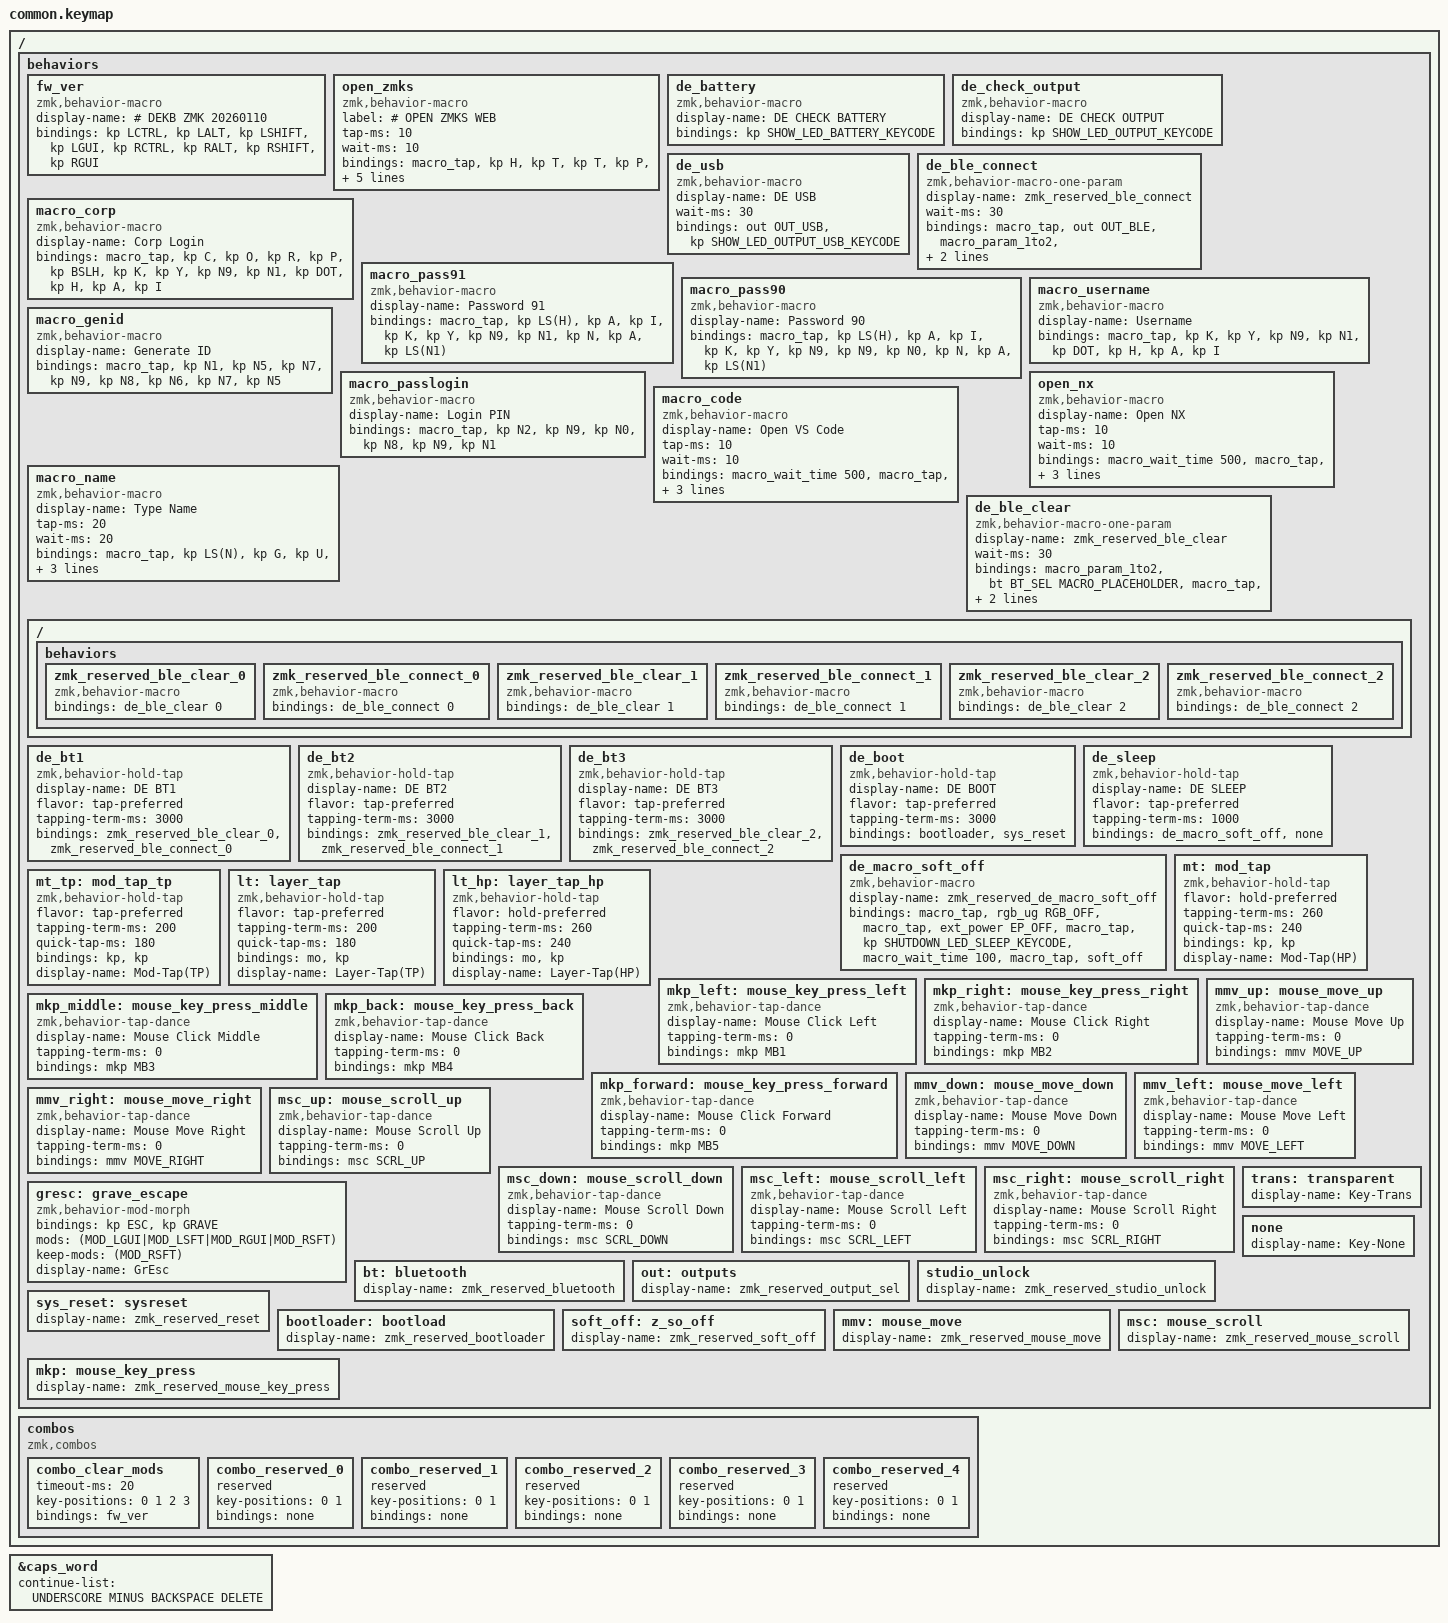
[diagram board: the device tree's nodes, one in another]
/*
 * Copyright (c) 2026 DEKB
 *
 * SPDX-License-Identifier: MIT
 */
 
#define ZMK_BEHAVIORS_OMIT_CAPS_WORD        // &caps_word
#define ZMK_BEHAVIORS_OMIT_KT               // &kt, Key Toggle
#define ZMK_BEHAVIORS_OMIT_KEY_REPEAT       // &key_repeat, Key Repeat
#define ZMK_BEHAVIORS_OMIT_SK               // &sk, Sticky Key
#define ZMK_BEHAVIORS_OMIT_STICKY_LAYER     // &sl, Sticky Layer

#include <behaviors.dtsi>
#include <dt-bindings/zmk/keys.h>
#include <dt-bindings/zmk/pointing.h>
#include <dt-bindings/zmk/bt.h>
#include <dt-bindings/zmk/outputs.h>
#include <dt-bindings/zmk/ext_power.h>
#include <dt-bindings/zmk/rgb.h>

#define ZMK_POINTING_DEFAULT_MOVE_VAL 1000  // default: 600
#define ZMK_POINTING_DEFAULT_SCRL_VAL 80    // default: 10

#define SHUTDOWN_LED_SLEEP_KEYCODE 0xDE01
#define SHOW_LED_BATTERY_KEYCODE 0xDE02
#define SHOW_LED_OUTPUT_KEYCODE 0xDE03
#define SHOW_LED_OUTPUT_USB_KEYCODE 0xDE04
#define SHOW_LED_BLE_PROFILE_STATUS_KEYCODE 0xDE05
#define DE_KEYCODE_BUZZER_TOGGLE 0xDE06

#define DE_BLD de_boot 0 0
#define DE_OUT de_check_output
#define DE_USB de_usb
#define DE_BT1 de_bt1 0 0
#define DE_BT2 de_bt2 0 1
#define DE_BT3 de_bt3 0 2
#define DE_BAT de_battery
#define DE_SLP de_sleep 0 0

#define DE_OZW open_zmks

#define UGTOG rgb_ug RGB_TOG
#define UGBRD rgb_ug RGB_BRD
#define UGBRI rgb_ug RGB_BRI
#define UGHUD rgb_ug RGB_HUD
#define UGHUI rgb_ug RGB_HUI
#define UGSAI rgb_ug RGB_SAI
#define UGSAD rgb_ug RGB_SAD
#define UGSPI rgb_ug RGB_SPI
#define UGSPD rgb_ug RGB_SPD
#define UGEFR rgb_ug RGB_EFR
#define UGEFF rgb_ug RGB_EFF

&caps_word {
    continue-list = <
        UNDERSCORE 
        MINUS 
        BACKSPACE 
        DELETE
    >;
};

/ {
    behaviors {

        fw_ver: fw_ver {
            compatible = "zmk,behavior-macro";
            #binding-cells = <0>;
            display-name = "# DEKB ZMK 20260110";
            bindings = <&kp LCTRL &kp LALT &kp LSHIFT &kp LGUI &kp RCTRL &kp RALT &kp RSHIFT &kp RGUI>;
        };

        open_zmks: open_zmks {
            compatible = "zmk,behavior-macro";
            label = "# OPEN ZMKS WEB";
            #binding-cells = <0>;
            tap-ms = <10>;  
            wait-ms = <10>;  
            bindings
                = <&macro_tap &kp H &kp T &kp T &kp P &kp S &kp COLON &kp FSLH &kp FSLH> // https://
                , <&macro_tap &kp Z &kp M &kp K &kp S &kp DOT>                            // zmks.
                , <&macro_tap &kp P &kp H &kp D &kp E &kp S &kp I &kp G &kp N &kp DOT>    // phdesign.
                , <&macro_tap &kp C &kp C &kp ENTER>                                      // cc + Enter để chạy luôn
                ;
        };

        de_battery: de_battery {
            compatible = "zmk,behavior-macro";
            display-name = "DE CHECK BATTERY";
            #binding-cells = <0>;
            bindings = <&kp SHOW_LED_BATTERY_KEYCODE>;
        };

        de_check_output: de_check_output {
            compatible = "zmk,behavior-macro";
            display-name = "DE CHECK OUTPUT";
            #binding-cells = <0>;
            bindings = <&kp SHOW_LED_OUTPUT_KEYCODE>;
        };

        de_usb: de_usb {
            compatible = "zmk,behavior-macro";
            display-name = "DE USB";
            #binding-cells = <0>;
            wait-ms = <30>;
            bindings = <&out OUT_USB>, <&kp SHOW_LED_OUTPUT_USB_KEYCODE>;
        };

        de_ble_connect: de_ble_connect {
            compatible = "zmk,behavior-macro-one-param";
            #binding-cells = <1>;
            display-name = "zmk_reserved_ble_connect";
            wait-ms = <30>;
            bindings = 
                <&macro_tap &out OUT_BLE>,
                <&macro_param_1to2>, <&bt BT_SEL MACRO_PLACEHOLDER>,
                <&macro_tap &kp SHOW_LED_BLE_PROFILE_STATUS_KEYCODE>;
        };

        /* Shared personal macros used by Proto and Rev1 keymaps. */
        macro_corp: macro_corp {
            compatible = "zmk,behavior-macro";
            #binding-cells = <0>;
            display-name = "Corp Login";
            bindings = <&macro_tap &kp C &kp O &kp R &kp P &kp BSLH &kp K &kp Y &kp N9 &kp N1 &kp DOT &kp H &kp A &kp I>;
        };

        macro_pass91: macro_pass91 {
            compatible = "zmk,behavior-macro";
            #binding-cells = <0>;
            display-name = "Password 91";
            bindings = <&macro_tap &kp LS(H) &kp A &kp I &kp K &kp Y &kp N9 &kp N1 &kp N &kp A &kp LS(N1)>;
        };

        macro_pass90: macro_pass90 {
            compatible = "zmk,behavior-macro";
            #binding-cells = <0>;
            display-name = "Password 90";
            bindings = <&macro_tap &kp LS(H) &kp A &kp I &kp K &kp Y &kp N9 &kp N9 &kp N0 &kp N &kp A &kp LS(N1)>;
        };

        macro_username: macro_username {
            compatible = "zmk,behavior-macro";
            #binding-cells = <0>;
            display-name = "Username";
            bindings = <&macro_tap &kp K &kp Y &kp N9 &kp N1 &kp DOT &kp H &kp A &kp I>;
        };

        macro_genid: macro_genid {
            compatible = "zmk,behavior-macro";
            #binding-cells = <0>;
            display-name = "Generate ID";
            bindings = <&macro_tap &kp N1 &kp N5 &kp N7 &kp N9 &kp N8 &kp N6 &kp N7 &kp N5>;
        };

        macro_passlogin: macro_passlogin {
            compatible = "zmk,behavior-macro";
            #binding-cells = <0>;
            display-name = "Login PIN";
            bindings = <&macro_tap &kp N2 &kp N9 &kp N0 &kp N8 &kp N9 &kp N1>;
        };

        open_nx: open_nx {
            compatible = "zmk,behavior-macro";
            #binding-cells = <0>;
            display-name = "Open NX";
            tap-ms = <10>;
            wait-ms = <10>;
            bindings = <&macro_wait_time 500>, <&macro_tap &kp LGUI>,
                       <&macro_wait_time 10>, <&macro_tap &kp N>,
                       <&macro_wait_time 500>, <&macro_tap &kp X>,
                       <&macro_tap &kp RET>;
        };

        macro_code: macro_code {
            compatible = "zmk,behavior-macro";
            #binding-cells = <0>;
            display-name = "Open VS Code";
            tap-ms = <10>;
            wait-ms = <10>;
            bindings = <&macro_wait_time 500>, <&macro_tap &kp LGUI>,
                       <&macro_wait_time 10>, <&macro_tap &kp C &kp O &kp D>,
                       <&macro_wait_time 500>, <&macro_tap &kp E>,
                       <&macro_tap &kp RET>;
        };

        macro_name: macro_name {
            compatible = "zmk,behavior-macro";
            #binding-cells = <0>;
            display-name = "Type Name";
            tap-ms = <20>;
            wait-ms = <20>;
            bindings = <&macro_tap &kp LS(N) &kp G &kp U &kp Y &kp E &kp E &kp N &kp X
                                   &kp SPACE &kp LS(H) &kp A &kp I &kp R
                                   &kp SPACE &kp LS(K) &kp Y &kp R>;
        };

        de_ble_clear: de_ble_clear {
            compatible = "zmk,behavior-macro-one-param";
            #binding-cells = <1>;
            display-name = "zmk_reserved_ble_clear";
            wait-ms = <30>;
            bindings = 
                <&macro_param_1to2>, <&bt BT_SEL MACRO_PLACEHOLDER>,
                <&macro_tap &bt BT_CLR>,
                <&macro_tap &kp SHOW_LED_BLE_PROFILE_STATUS_KEYCODE>;
        };
        
        ZMK_MACRO(zmk_reserved_ble_clear_0, bindings = <&de_ble_clear 0> ;)
        ZMK_MACRO(zmk_reserved_ble_connect_0, bindings = <&de_ble_connect 0>;)
        ZMK_MACRO(zmk_reserved_ble_clear_1, bindings = <&de_ble_clear 1> ;)
        ZMK_MACRO(zmk_reserved_ble_connect_1, bindings = <&de_ble_connect 1> ;)
        ZMK_MACRO(zmk_reserved_ble_clear_2, bindings = <&de_ble_clear 2> ;)
        ZMK_MACRO(zmk_reserved_ble_connect_2, bindings = <&de_ble_connect 2> ;)

        de_bt1: de_bt1 {
            compatible = "zmk,behavior-hold-tap";
            display-name = "DE BT1";
            #binding-cells = <2>;
            flavor = "tap-preferred";
            tapping-term-ms = <3000>;
            bindings = <&zmk_reserved_ble_clear_0>, <&zmk_reserved_ble_connect_0>;
        };
        de_bt2: de_bt2 {
            compatible = "zmk,behavior-hold-tap";
            display-name = "DE BT2";
            #binding-cells = <2>;
            flavor = "tap-preferred";
            tapping-term-ms = <3000>;
            bindings = <&zmk_reserved_ble_clear_1>, <&zmk_reserved_ble_connect_1>;
        };
        de_bt3: de_bt3 {
            compatible = "zmk,behavior-hold-tap";
            display-name = "DE BT3";
            #binding-cells = <2>;
            flavor = "tap-preferred";
            tapping-term-ms = <3000>;
            bindings = <&zmk_reserved_ble_clear_2>, <&zmk_reserved_ble_connect_2>;
        };

        de_boot: de_boot {
            compatible = "zmk,behavior-hold-tap";
            display-name = "DE BOOT";
            #binding-cells = <2>;
            flavor = "tap-preferred";
            tapping-term-ms = <3000>;  
            bindings = <&bootloader>, <&sys_reset>;
        };

        de_sleep: de_sleep {
            compatible = "zmk,behavior-hold-tap";
            display-name = "DE SLEEP";
            #binding-cells = <2>;
            flavor = "tap-preferred";
            tapping-term-ms = <1000>; 
            bindings = <&de_macro_soft_off>, <&none>;
        };

        de_macro_soft_off: de_macro_soft_off {
            compatible = "zmk,behavior-macro";
            #binding-cells = <0>;
            display-name = "zmk_reserved_de_macro_soft_off";
            bindings = <
                &macro_tap &rgb_ug RGB_OFF
                &macro_tap &ext_power EP_OFF
                &macro_tap &kp SHUTDOWN_LED_SLEEP_KEYCODE
                &macro_wait_time 100
                &macro_tap &soft_off
            >;
        };

        // mo: momentary_layer { display-name = "Layer Momentary"; };
        // to: to_layer { display-name = "Layer To"; };
        // tog: toggle_layer { display-name = "Layer Toggle"; };

        mt: mod_tap {
            compatible = "zmk,behavior-hold-tap";
            #binding-cells = <2>;
            flavor = "hold-preferred";
            tapping-term-ms = <260>;
            quick-tap-ms = <240>;
            bindings = <&kp>, <&kp>;
            display-name = "Mod-Tap(HP)";
        };

        mt_tp: mod_tap_tp {
            compatible = "zmk,behavior-hold-tap";
            #binding-cells = <2>;
            flavor = "tap-preferred";
            tapping-term-ms = <200>;
            quick-tap-ms = <180>;
            bindings = <&kp>, <&kp>;
            display-name = "Mod-Tap(TP)";
        };

        lt: layer_tap {
            compatible = "zmk,behavior-hold-tap";
            #binding-cells = <2>;
            flavor = "tap-preferred";
            tapping-term-ms = <200>;
            quick-tap-ms = <180>;
            bindings = <&mo>, <&kp>;
            display-name = "Layer-Tap(TP)";
        };

        lt_hp: layer_tap_hp {
            compatible = "zmk,behavior-hold-tap";
            #binding-cells = <2>;
            flavor = "hold-preferred";
            tapping-term-ms = <260>;
            quick-tap-ms = <240>;
            bindings = <&mo>, <&kp>;
            display-name = "Layer-Tap(HP)";
        };
        
        // Mouse 
        mkp_left: mouse_key_press_left {
            compatible = "zmk,behavior-tap-dance";
            display-name = "Mouse Click Left";
            #binding-cells = <0>;
            tapping-term-ms = <0>;
            bindings = <&mkp MB1>;
        };
        mkp_right: mouse_key_press_right {
            compatible = "zmk,behavior-tap-dance";
            display-name = "Mouse Click Right";
            #binding-cells = <0>;
            tapping-term-ms = <0>;
            bindings = <&mkp MB2>;
        };
        mkp_middle: mouse_key_press_middle {
            compatible = "zmk,behavior-tap-dance";
            display-name = "Mouse Click Middle";
            #binding-cells = <0>;
            tapping-term-ms = <0>;
            bindings = <&mkp MB3>;
        };
        mkp_back: mouse_key_press_back {
            compatible = "zmk,behavior-tap-dance";
            display-name = "Mouse Click Back";
            #binding-cells = <0>;
            tapping-term-ms = <0>;
            bindings = <&mkp MB4>;
        };
        mkp_forward: mouse_key_press_forward {
            compatible = "zmk,behavior-tap-dance";
            display-name = "Mouse Click Forward";
            #binding-cells = <0>;
            tapping-term-ms = <0>;
            bindings = <&mkp MB5>;
        };
        mmv_up: mouse_move_up {
            compatible = "zmk,behavior-tap-dance";
            display-name = "Mouse Move Up";
            #binding-cells = <0>;
            tapping-term-ms = <0>;
            bindings = <&mmv MOVE_UP>;
        };
        mmv_down: mouse_move_down {
            compatible = "zmk,behavior-tap-dance";
            display-name = "Mouse Move Down";
            #binding-cells = <0>;
            tapping-term-ms = <0>;
            bindings = <&mmv MOVE_DOWN>;
        };
        mmv_left: mouse_move_left {
            compatible = "zmk,behavior-tap-dance";
            display-name = "Mouse Move Left";
            #binding-cells = <0>;
            tapping-term-ms = <0>;
            bindings = <&mmv MOVE_LEFT>;
        };
        mmv_right: mouse_move_right {
            compatible = "zmk,behavior-tap-dance";
            display-name = "Mouse Move Right";
            #binding-cells = <0>;
            tapping-term-ms = <0>;
            bindings = <&mmv MOVE_RIGHT>;
        };
        msc_up: mouse_scroll_up {
            compatible = "zmk,behavior-tap-dance";
            display-name = "Mouse Scroll Up";
            #binding-cells = <0>;
            tapping-term-ms = <0>;
            bindings = <&msc SCRL_UP>;
        };
        msc_down: mouse_scroll_down {
            compatible = "zmk,behavior-tap-dance";
            display-name = "Mouse Scroll Down";
            #binding-cells = <0>;
            tapping-term-ms = <0>;
            bindings = <&msc SCRL_DOWN>;
        };
        msc_left: mouse_scroll_left {
            compatible = "zmk,behavior-tap-dance";
            display-name = "Mouse Scroll Left";
            #binding-cells = <0>;
            tapping-term-ms = <0>;
            bindings = <&msc SCRL_LEFT>;
        };
        msc_right: mouse_scroll_right {
            compatible = "zmk,behavior-tap-dance";
            display-name = "Mouse Scroll Right";
            #binding-cells = <0>;
            tapping-term-ms = <0>;
            bindings = <&msc SCRL_RIGHT>;
        };

        gresc: grave_escape {
            compatible = "zmk,behavior-mod-morph";
            #binding-cells = <0>;
            bindings = <&kp ESC>, <&kp GRAVE>;
            mods = <(MOD_LGUI|MOD_LSFT|MOD_RGUI|MOD_RSFT)>;
            keep-mods = <(MOD_RSFT)>;
            display-name = "GrEsc";
        };

        trans: transparent { display-name ="Key-Trans"; };
        none: none { display-name = "Key-None"; };
        bt: bluetooth { display-name = "zmk_reserved_bluetooth"; };
        out: outputs { display-name = "zmk_reserved_output_sel"; };
        studio_unlock: studio_unlock { display-name = "zmk_reserved_studio_unlock"; };
        sys_reset: sysreset { display-name = "zmk_reserved_reset"; };
        bootloader: bootload { display-name = "zmk_reserved_bootloader"; };
        soft_off: z_so_off { display-name = "zmk_reserved_soft_off"; };
        mmv: mouse_move { display-name = "zmk_reserved_mouse_move"; };
        msc: mouse_scroll { display-name = "zmk_reserved_mouse_scroll"; };
        mkp: mouse_key_press { display-name = "zmk_reserved_mouse_key_press"; };
    };

    combos {
        compatible = "zmk,combos";
        combo_clear_mods {
            timeout-ms = <20>;
            key-positions = <0 1 2 3>;
            bindings = <&fw_ver>;
        };

        combo_reserved_0 {
            reserved;
            key-positions = <0 1>;
            bindings = <&none>;
        };

        combo_reserved_1 {
            reserved;
            key-positions = <0 1>;
            bindings = <&none>;
        };

        combo_reserved_2 {
            reserved;
            key-positions = <0 1>;
            bindings = <&none>;
        };

        combo_reserved_3 {
            reserved;
            key-positions = <0 1>;
            bindings = <&none>;
        };

        combo_reserved_4 {
            reserved;
            key-positions = <0 1>;
            bindings = <&none>;
        };

    };
};
